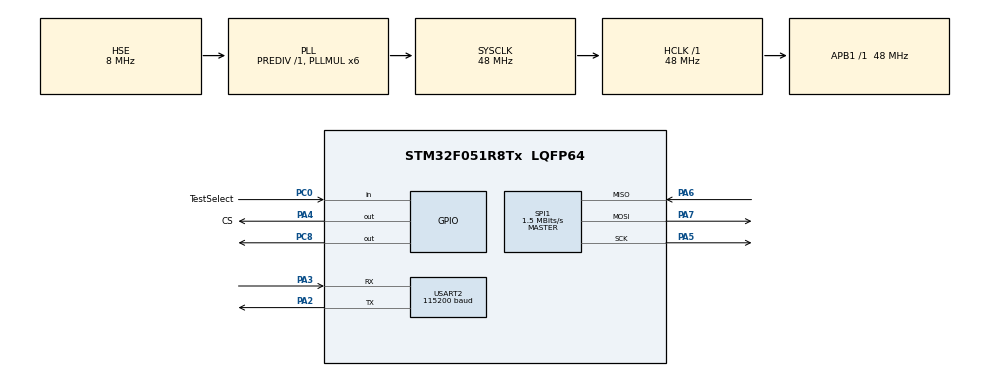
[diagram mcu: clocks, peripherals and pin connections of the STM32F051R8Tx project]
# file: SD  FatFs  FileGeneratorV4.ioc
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Dma.Request0=SPI1_RX
Dma.Request1=SPI1_TX
Dma.SPI1_RX.0.Direction=DMA_PERIPH_TO_MEMORY
Dma.SPI1_RX.0.Instance=DMA1_Channel2
Dma.SPI1_RX.0.MemDataAlignment=DMA_MDATAALIGN_BYTE
Dma.SPI1_RX.0.MemInc=DMA_MINC_ENABLE
Dma.SPI1_RX.0.Mode=DMA_NORMAL
Dma.SPI1_RX.0.PeriphDataAlignment=DMA_PDATAALIGN_BYTE
Dma.SPI1_RX.0.PeriphInc=DMA_PINC_DISABLE
Dma.SPI1_RX.0.Priority=DMA_PRIORITY_LOW
Dma.SPI1_TX.1.Direction=DMA_MEMORY_TO_PERIPH
Dma.SPI1_TX.1.Instance=DMA1_Channel3
Dma.SPI1_TX.1.MemDataAlignment=DMA_MDATAALIGN_BYTE
Dma.SPI1_TX.1.MemInc=DMA_MINC_ENABLE
Dma.SPI1_TX.1.Mode=DMA_NORMAL
Dma.SPI1_TX.1.PeriphDataAlignment=DMA_PDATAALIGN_BYTE
Dma.SPI1_TX.1.PeriphInc=DMA_PINC_DISABLE
Dma.SPI1_TX.1.Priority=DMA_PRIORITY_LOW
FATFS._USE_LABEL=1
FATFS._USE_LFN=3
Mcu.Family=STM32F0
Mcu.Name=STM32F051R8Tx
Mcu.Package=LQFP64
NVIC.DMA1_Channel2_3_IRQn=true\:0\:0\:false\:false\:true\:false\:true\:true
NVIC.USART2_IRQn=true\:0\:0\:false\:false\:true\:true\:true\:true
PA2.Mode=Asynchronous
PA2.Signal=USART2_TX
PA3.Mode=Asynchronous
PA3.Signal=USART2_RX
PA4.GPIO_Label=CS
PA4.GPIO_Speed=GPIO_SPEED_FREQ_HIGH
PA4.PinState=GPIO_PIN_SET
PA4.Signal=GPIO_Output
PA5.Mode=Full_Duplex_Master
PA5.Signal=SPI1_SCK
PA6.Mode=Full_Duplex_Master
PA6.Signal=SPI1_MISO
PA7.Mode=Full_Duplex_Master
PA7.Signal=SPI1_MOSI
PC0.GPIO_Label=TestSelect
PC0.GPIO_Mode=GPIO_MODE_INPUT
PC0.GPIO_PuPd=GPIO_PULLDOWN
PC0.Signal=GPIO_Input
PC14-OSC32_IN.Mode=LSE-External-Oscillator
PC14-OSC32_IN.Signal=RCC_OSC32_IN
PC15-OSC32_OUT.Mode=LSE-External-Oscillator
PC15-OSC32_OUT.Signal=RCC_OSC32_OUT
PC8.Signal=GPIO_Output
PF0-OSC_IN.Mode=HSE-External-Oscillator
PF0-OSC_IN.Signal=RCC_OSC_IN
PF1-OSC_OUT.Mode=HSE-External-Oscillator
PF1-OSC_OUT.Signal=RCC_OSC_OUT
ProjectManager.HeapSize=0x200
ProjectManager.StackSize=0x400
ProjectManager.TargetToolchain=STM32CubeIDE
RCC.AHBFreq_Value=48000000
RCC.APB1Freq_Value=48000000
RCC.APB1TimFreq_Value=48000000
RCC.HCLKFreq_Value=48000000
RCC.PLLMUL=RCC_PLL_MUL6
RCC.PLLSourceVirtual=RCC_PLLSOURCE_HSE
RCC.SYSCLKFreq_VALUE=48000000
RCC.SYSCLKSource=RCC_SYSCLKSOURCE_PLLCLK
SPI1.BaudRatePrescaler=SPI_BAUDRATEPRESCALER_32
SPI1.CalculateBaudRate=1.5 MBits/s
SPI1.DataSize=SPI_DATASIZE_8BIT
SPI1.Direction=SPI_DIRECTION_2LINES
SPI1.Mode=SPI_MODE_MASTER
SPI1.VirtualType=VM_MASTER
USART2.BaudRate=115200
USART2.VirtualMode-Asynchronous=VM_ASYNC
VP_FATFS_VS_Generic.Mode=User_defined
board=custom

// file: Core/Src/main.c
/* USER CODE BEGIN Header */
/**
  ******************************************************************************
  * @file           : main.c
  * @brief          : Main program body
  ******************************************************************************
  * @attention
  *
  * Copyright (c) 2025 STMicroelectronics.
  * All rights reserved.
  *
  * This software is licensed under terms that can be found in the LICENSE file
  * in the root directory of this software component.
  * If no LICENSE file comes with this software, it is provided AS-IS.
  *
  ******************************************************************************
  */
/* USER CODE END Header */
#include "main.h"
#include "dma.h"
#include "fatfs.h"
#include "spi.h"
#include "usart.h"
#include "gpio.h"

/* USER CODE BEGIN Includes */

#include <stdio.h>

esto se va a mantener

/* USER CODE END Includes */

void SystemClock_Config(void);

/* USER CODE BEGIN 0 */

int _write(int fd, unsigned char *buf, int len) {
  if (fd == 1 || fd == 2) {                     // stdout or stderr ?
    HAL_UART_Transmit(&huart2, buf, len, 999);  // Print to the UART
  }
  return len;
}

/* USER CODE END 0 */

int main(void)
{

  /* MCU Configuration--------------------------------------------------------*/

  /* Reset of all peripherals, Initializes the Flash interface and the Systick. */
  HAL_Init();

  /* Configure the system clock */
  SystemClock_Config();

  /* Initialize all configured peripherals */
  MX_GPIO_Init();
  MX_DMA_Init();
  MX_SPI1_Init();
  MX_USART2_UART_Init();
  /* USER CODE BEGIN 2 */

  char fileName[32];
  char folderPath[64];

  const char *initalText;

  initalText = "hola";

  sd_create_and_write_file(fileName, sizeof(fileName), folderPath, sizeof(folderPath), initalText);

  // Escribe texto inicial en el archivo
  for(int i;i<10;i++){
	  sd_append_file_with_directory(fileName, "sda\n", folderPath);
  }

  sd_unmount();

  /* USER CODE END 2 */

  /* Infinite loop */
  while (1)
  {

  }
}

void SystemClock_Config(void)
{
  RCC_OscInitTypeDef RCC_OscInitStruct = {0};
  RCC_ClkInitTypeDef RCC_ClkInitStruct = {0};

  /** Initializes the RCC Oscillators according to the specified parameters
  * in the RCC_OscInitTypeDef structure.
  */
  RCC_OscInitStruct.OscillatorType = RCC_OSCILLATORTYPE_HSE;
  RCC_OscInitStruct.HSEState = RCC_HSE_ON;
  RCC_OscInitStruct.PLL.PLLState = RCC_PLL_ON;
  RCC_OscInitStruct.PLL.PLLSource = RCC_PLLSOURCE_HSE;
  RCC_OscInitStruct.PLL.PLLMUL = RCC_PLL_MUL6;
  RCC_OscInitStruct.PLL.PREDIV = RCC_PREDIV_DIV1;
  if (HAL_RCC_OscConfig(&RCC_OscInitStruct) != HAL_OK)
  {
    Error_Handler();
  }

  /** Initializes the CPU, AHB and APB buses clocks
  */
  RCC_ClkInitStruct.ClockType = RCC_CLOCKTYPE_HCLK|RCC_CLOCKTYPE_SYSCLK
                              |RCC_CLOCKTYPE_PCLK1;
  RCC_ClkInitStruct.SYSCLKSource = RCC_SYSCLKSOURCE_PLLCLK;
  RCC_ClkInitStruct.AHBCLKDivider = RCC_SYSCLK_DIV1;
  RCC_ClkInitStruct.APB1CLKDivider = RCC_HCLK_DIV1;

  if (HAL_RCC_ClockConfig(&RCC_ClkInitStruct, FLASH_LATENCY_1) != HAL_OK)
  {
    Error_Handler();
  }
}

void Error_Handler(void)
{
  __disable_irq();
  while (1)
  {
  }
}
